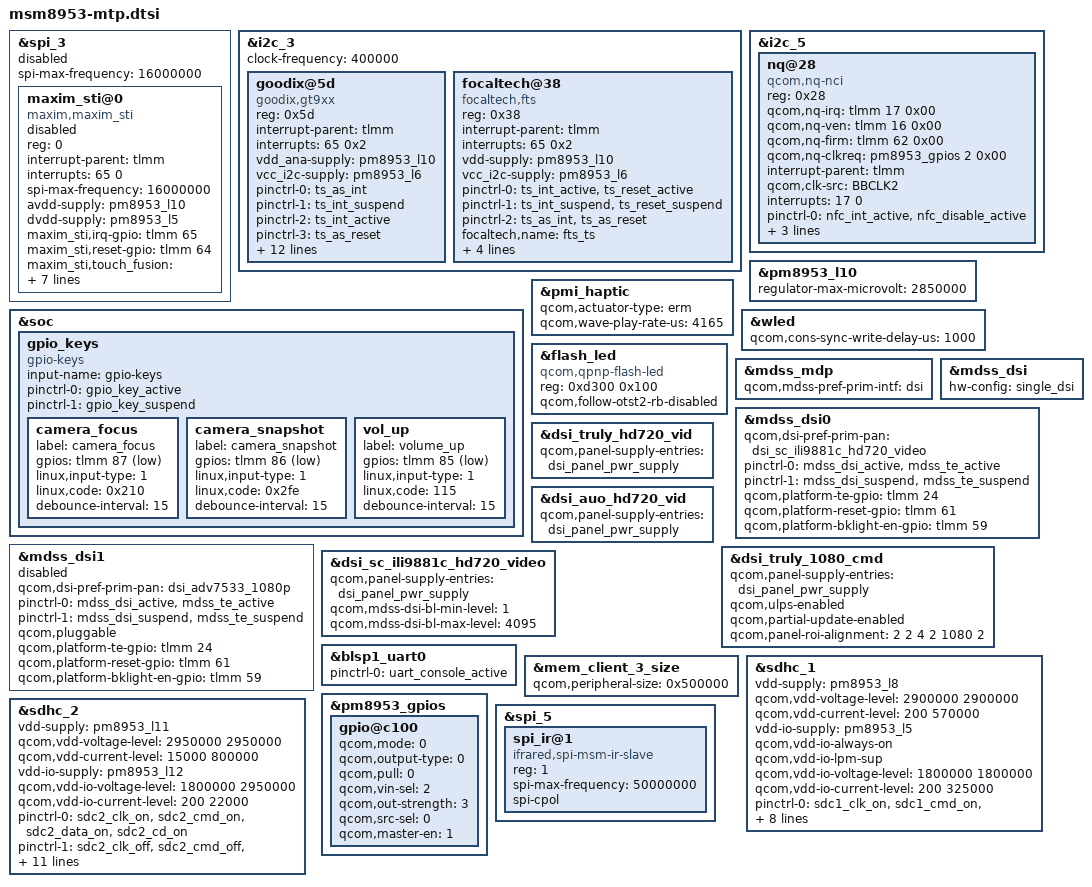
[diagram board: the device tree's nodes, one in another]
/*
 * Copyright (c) 2015-2018, The Linux Foundation. All rights reserved.
 * Copyright (C) 2019 XiaoMi, Inc.
 *
 * This program is free software; you can redistribute it and/or modify
 * it under the terms of the GNU General Public License version 2 and
 * only version 2 as published by the Free Software Foundation.
 *
 * This program is distributed in the hope that it will be useful,
 * but WITHOUT ANY WARRANTY; without even the implied warranty of
 * MERCHANTABILITY or FITNESS FOR A PARTICULAR PURPOSE.  See the
 * GNU General Public License for more details.
 */

#include "msm8953-pinctrl.dtsi"
#include "msm8953-audio-mtp.dtsi"

&spi_3 { /* BLSP1 QUP3 */
	status = "disabled";   /*modify by shenwenbin for disable spi3 to release gpio 20181228 */
	spi-max-frequency = <16000000>;
	maxim_sti@0 {
		status = "disabled";
		compatible = "maxim,maxim_sti";
		reg = <0>;
		interrupt-parent = <&tlmm>;
		interrupts = <65 0>;
		spi-max-frequency = <16000000>;
		avdd-supply = <&pm8953_l10>;
		dvdd-supply = <&pm8953_l5>;
		maxim_sti,irq-gpio = <&tlmm 65 0x00>;
		maxim_sti,reset-gpio = <&tlmm 64 0x00>;
		maxim_sti,touch_fusion = "/vendor/bin/touch_fusion";
		maxim_sti,config_file = "/etc/firmware/qtc800s.cfg";
		maxim_sti,fw_name = "qtc800s.bin";
		pinctrl-names = "pmx_ts_active","pmx_ts_suspend",
						"pmx_ts_release";
		pinctrl-0 = <&ts_int_active &ts_reset_active>;
		pinctrl-1 = <&ts_int_suspend &ts_reset_suspend>;
		pinctrl-2 = <&ts_release>;
	};
};

/*modify by shenwenbin for merge 8.1 base 20181228 begin*/
&i2c_3 {
	status = "ok";
	clock-frequency = <400000>;

	goodix@5d{
		compatible = "goodix,gt9xx";
		reg = <0x5d>;
		interrupt-parent = <&tlmm>;
		interrupts = <65 0x2>;
		vdd_ana-supply = <&pm8953_l10>;
		vcc_i2c-supply = <&pm8953_l6>;
		// pins used by touchscreen
		pinctrl-names = "eint_as_int","eint_output_low", "eint_output_high",
		"erst_as_default","erst_output_low","erst_output_high";
                pinctrl-0 = <&ts_as_int>;
                pinctrl-1 = <&ts_int_suspend>;
                pinctrl-2 = <&ts_int_active>;
                pinctrl-3 = <&ts_as_reset>;
                pinctrl-4 = <&ts_reset_suspend>;
                pinctrl-5 = <&ts_reset_active>;
		goodix,family-id = <0x09>;
		goodix,product-id = "9111";
		goodix,reset-gpio = <&tlmm 64 0x00>;
		//goodix,power_ldo-gpio = <&tlmm 0 0x00>;
		goodix,irq-gpio = <&tlmm 65 0x00>;
		goodix,display-coords = <0 720 0 1440>;
		goodix,panel-coords = <0 720 0 1440>;
		//goodix,button-map = <158 102 139>;
		//goodix,fw-auto-update;
		//goodix,force-update;
		goodix,i2c-pull-up;
		goodix,dbl_clk_wakeup;
		goodix,cfg-group0 = [
                     52 D0 02 A0 05 0A 3C 10 11 5A 37
                     0F 5A 46 08 62 00 00 00 00 12 13
                     02 30 00 00 2E 87 27 EE 32 34 64
                     09 0F 0A 00 C3 33 91 00 00 00 00
                     00 A3 40 0A 0F DC 22 19 46 83 E0
                     A4 19 28 23 04 CF 1B 00 AF 21 00
                     8A 2D 00 73 3B 00 6A 43 00 68 00
                     00 00 00 00 00 00 00 00 00 4B 02
                     00 00 00 00 00 00 00 02 00 00 28
                     28 00 00 00 00 00 07 5A 00 00 00
                     00 32 0D 0C 0B 0A 09 08 07 06 05
                     04 03 02 01 00 1B 1A 19 18 17 16
                     15 14 13 12 11 10 0F 0E FF FF 2A
                     29 24 22 20 1F 1E 0A 08 06 05 04
                     02 00 FF FF FF 00 00 00 00 00 00
                     00 00 00 37 41 4B 0A 1E 37 F6 0A
                     00 99 99 2D 1F 48 84 D8 00 00 00
                     00 00 00 28 50 00 00 00 0A 5E 14
                     80 00 01 0F 78 46 65 1E 86 40 28
                     33 62 0F 50 19 00 00 85 44 1E 3A
                     0F 0F 28 64 0F 25 D3 01
                ];
	};

	focaltech@38{
		compatible = "focaltech,fts";
		reg = <0x38>;
		interrupt-parent = <&tlmm>;
		interrupts = <65 0x2>;
		vdd-supply = <&pm8953_l10>;
		vcc_i2c-supply = <&pm8953_l6>;
		/* pins used by touchscreen */
                pinctrl-names = "pmx_ts_irqrst_active","pmx_ts_irqrst_suspend",
                    "pmx_ts_irqrst_release";
                pinctrl-0 = <&ts_int_active &ts_reset_active>;
                pinctrl-1 = <&ts_int_suspend &ts_reset_suspend>;
                pinctrl-2 = <&ts_as_int &ts_as_reset>;
		focaltech,name = "fts_ts";
		focaltech,reset-gpio = <&tlmm 64 0x00>;
		//focaltech,power_ldo-gpio = <&tlmm 0 0x00>;
		focaltech,irq-gpio = <&tlmm 65 0x02>;
		focaltech,display-coords = <0 0 720 1440>;
		focaltech,max-touch-number = <10>;
		/*focaltech,have-key;
		focaltech,key-number = <3>;
		focaltech,keys = <139 172 158>;
		focaltech,key-y-coord = <1350>;
		focaltech,key-x-coords = <180 350 540>;*/
	};
};
/*modify by shenwenbin for merge 8.1 base 20181228 end*/

&i2c_5 { /* BLSP2 QUP1 (NFC) */
	nq@28 {
		compatible = "qcom,nq-nci";
		reg = <0x28>;
		qcom,nq-irq = <&tlmm 17 0x00>;
		qcom,nq-ven = <&tlmm 16 0x00>;
		qcom,nq-firm = <&tlmm 62 0x00>;
		qcom,nq-clkreq = <&pm8953_gpios 2 0x00>;
		interrupt-parent = <&tlmm>;
		qcom,clk-src = "BBCLK2";
		interrupts = <17 0>;
		interrupt-names = "nfc_irq";
		pinctrl-names = "nfc_active", "nfc_suspend";
		pinctrl-0 = <&nfc_int_active &nfc_disable_active>;
		pinctrl-1 = <&nfc_int_suspend &nfc_disable_suspend>;
		clocks = <&clock_gcc clk_bb_clk2_pin>;
		clock-names = "ref_clk";
	};
};

&pm8953_l10 {
	regulator-max-microvolt = <2850000>;
};

&soc {
	gpio_keys {
		compatible = "gpio-keys";
		input-name = "gpio-keys";
		pinctrl-names = "tlmm_gpio_key_active","tlmm_gpio_key_suspend";
		pinctrl-0 = <&gpio_key_active>;
		pinctrl-1 = <&gpio_key_suspend>;

		camera_focus {
			label = "camera_focus";
			gpios = <&tlmm 87 0x1>;
			linux,input-type = <1>;
			linux,code = <0x210>;
			debounce-interval = <15>;
		};

		camera_snapshot {
			label = "camera_snapshot";
			gpios = <&tlmm 86 0x1>;
			linux,input-type = <1>;
			linux,code = <0x2fe>;
			debounce-interval = <15>;
		};

		vol_up {
			label = "volume_up";
			gpios = <&tlmm 85 0x1>;
			linux,input-type = <1>;
			linux,code = <115>;
			debounce-interval = <15>;
		};
	};

/*
	hbtp {
		compatible = "qcom,hbtp-input";
		vcc_ana-supply = <&pm8953_l10>;
		vcc_dig-supply = <&pm8953_l5>;
		qcom,afe-load = <50000>;
		qcom,afe-vtg-min = <2850000>;
		qcom,afe-vtg-max = <2850000>;
		qcom,dig-load = <15000>;
		qcom,dig-vtg-min = <1800000>;
		qcom,dig-vtg-max = <1800000>;
	};
*/
};

/*modified vibrate by wangyibo at 20190109 start*/
&pmi_haptic{
	qcom,actuator-type = "erm";
//	qcom,lra-auto-res-mode="qwd";
//	qcom,lra-high-z="opt1";
//	qcom,lra-res-cal-period = <0>;
	qcom,wave-play-rate-us = <4165>;
};
/*modified vibrate by wangyibo at 20190109 end*/

&wled {
	qcom,cons-sync-write-delay-us = <1000>;
};

&flash_led {
	compatible = "qcom,qpnp-flash-led";
	reg = <0xd300 0x100>;
	qcom,follow-otst2-rb-disabled;
};

#include "msm8953-mdss-panels.dtsi"

&mdss_mdp {
	qcom,mdss-pref-prim-intf = "dsi";
};

&mdss_dsi {
	hw-config = "single_dsi";
};

&mdss_dsi0 {
	qcom,dsi-pref-prim-pan = <&dsi_sc_ili9881c_hd720_video>;
	pinctrl-names = "mdss_default", "mdss_sleep";
	pinctrl-0 = <&mdss_dsi_active &mdss_te_active>;
	pinctrl-1 = <&mdss_dsi_suspend &mdss_te_suspend>;

	qcom,platform-te-gpio = <&tlmm 24 0>;
	qcom,platform-reset-gpio = <&tlmm 61 0>;
	qcom,platform-bklight-en-gpio = <&tlmm 59 0>;
};

&mdss_dsi1 {
	status = "disabled";
	qcom,dsi-pref-prim-pan = <&dsi_adv7533_1080p>;
	pinctrl-names = "mdss_default", "mdss_sleep";
	pinctrl-0 = <&mdss_dsi_active &mdss_te_active>;
	pinctrl-1 = <&mdss_dsi_suspend &mdss_te_suspend>;

	qcom,pluggable;
	qcom,platform-te-gpio = <&tlmm 24 0>;
	qcom,platform-reset-gpio = <&tlmm 61 0>;
	qcom,platform-bklight-en-gpio = <&tlmm 59 0>;
};

&dsi_truly_hd720_vid {
	qcom,panel-supply-entries = <&dsi_panel_pwr_supply>;
//	qcom,mdss-dsi-pan-enable-dynamic-fps;
//	qcom,mdss-dsi-pan-fps-update = "dfps_immediate_clk_mode";
};

&dsi_auo_hd720_vid {
	qcom,panel-supply-entries = <&dsi_panel_pwr_supply>;
//	qcom,mdss-dsi-pan-enable-dynamic-fps;
//	qcom,mdss-dsi-pan-fps-update = "dfps_immediate_clk_mode";
};

&dsi_truly_1080_cmd {
	qcom,panel-supply-entries = <&dsi_panel_pwr_supply>;
	qcom,ulps-enabled;
	qcom,partial-update-enabled;
	qcom,panel-roi-alignment = <2 2 4 2 1080 2>;
};

&dsi_sc_ili9881c_hd720_video{

	qcom,panel-supply-entries = <&dsi_panel_pwr_supply>;
	qcom,mdss-dsi-bl-min-level = <1>;
	qcom,mdss-dsi-bl-max-level = <4095>;
//	qcom,mdss-dsi-pan-enable-dynamic-fps;
//	qcom,mdss-dsi-pan-fps-update = "dfps_immediate_clk_mode";
};
&blsp1_uart0 {
	status = "ok";
	pinctrl-names = "default";
	pinctrl-0 = <&uart_console_active>;
};

&mem_client_3_size {
	qcom,peripheral-size = <0x500000>;
};

&sdhc_1 {
	/* device core power supply */
	vdd-supply = <&pm8953_l8>;
	qcom,vdd-voltage-level = <2900000 2900000>;
	qcom,vdd-current-level = <200 570000>;

	/* device communication power supply */
	vdd-io-supply = <&pm8953_l5>;
	qcom,vdd-io-always-on;
	qcom,vdd-io-lpm-sup;
	qcom,vdd-io-voltage-level = <1800000 1800000>;
	qcom,vdd-io-current-level = <200 325000>;

	pinctrl-names = "active", "sleep";
	pinctrl-0 = <&sdc1_clk_on &sdc1_cmd_on &sdc1_data_on  &sdc1_rclk_on>;
	pinctrl-1 = <&sdc1_clk_off &sdc1_cmd_off &sdc1_data_off &sdc1_rclk_off>;

	qcom,clk-rates = <400000 20000000 25000000 50000000 100000000 192000000
								384000000>;
	qcom,nonremovable;
	qcom,bus-speed-mode = "HS400_1p8v", "HS200_1p8v", "DDR_1p8v";

	status = "ok";
};

&sdhc_2 {
	/* device core power supply */
	vdd-supply = <&pm8953_l11>;
	qcom,vdd-voltage-level = <2950000 2950000>;
	qcom,vdd-current-level = <15000 800000>;

	/* device communication power supply */
	vdd-io-supply = <&pm8953_l12>;
	qcom,vdd-io-voltage-level = <1800000 2950000>;
	qcom,vdd-io-current-level = <200 22000>;

	pinctrl-names = "active", "sleep";
	pinctrl-0 = <&sdc2_clk_on &sdc2_cmd_on &sdc2_data_on &sdc2_cd_on>;
	pinctrl-1 = <&sdc2_clk_off &sdc2_cmd_off &sdc2_data_off>;

	#address-cells = <0>;
	interrupt-parent = <&sdhc_2>;
	interrupts = <0 1 2>;
	#interrupt-cells = <1>;
	interrupt-map-mask = <0xffffffff>;
	interrupt-map = <0 &intc 0 125 0
		1 &intc 0 221 0
		2 &tlmm 133 0>;
	interrupt-names = "hc_irq", "pwr_irq", "status_irq";
	cd-gpios = <&tlmm 133 0x0>;

	qcom,clk-rates = <400000 20000000 25000000 50000000 100000000
								200000000>;
	qcom,bus-speed-mode = "SDR12", "SDR25", "SDR50", "DDR50", "SDR104";

	status = "ok";
};

/*&pm8953_typec {
	ss-mux-supply = <&pm8953_l13>;
	qcom,ssmux-gpio = <&tlmm 139 GPIO_ACTIVE_HIGH>;
	pinctrl-names = "default";
	pinctrl-0 = <&typec_ssmux_config>;
};*/

&pm8953_gpios {
	/* GPIO 2 (NFC_CLK_REQ) */
	gpio@c100 {
		qcom,mode = <0>;
		qcom,output-type = <0>;
		qcom,pull = <0>;
		qcom,vin-sel = <2>;
		qcom,out-strength = <3>;
		qcom,src-sel = <0>;
		qcom,master-en = <1>;
		status = "okay";
	};
};

&spi_5 {
	status = "ok";
	    spi_ir@1 {
	        compatible = "ifrared,spi-msm-ir-slave";
	        reg = <1>; /* Chip select 0 */
	        spi-max-frequency = <50000000>;
	        spi-cpol;
	        status = "ok";
	    };
};
